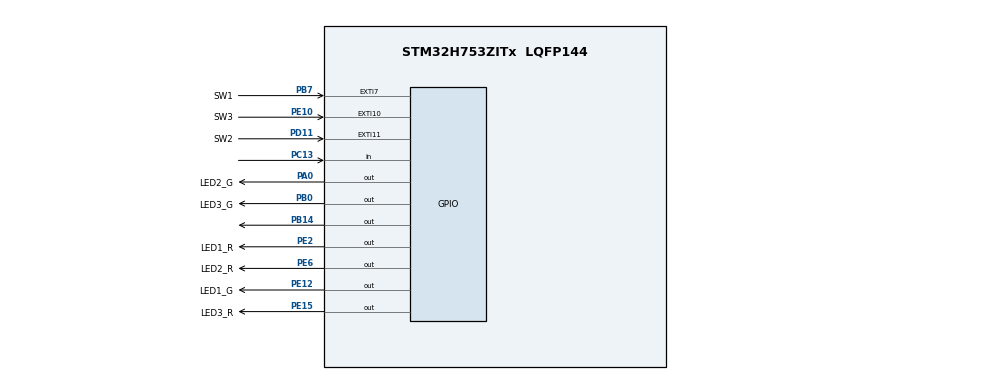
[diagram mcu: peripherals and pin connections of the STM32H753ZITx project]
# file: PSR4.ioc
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CORTEX_M7.CPU_DCache=Enabled
CORTEX_M7.CPU_ICache=Disabled
CORTEX_M7.MPU_Control=__NULL
CORTEX_M7.default_mode_Activation=1
Mcu.Family=STM32H7
Mcu.Name=STM32H753ZITx
Mcu.Package=LQFP144
NUCLEO-H753ZI.BUTTON=0
NUCLEO-H753ZI.LD1=false
NUCLEO-H753ZI.LD2=false
NUCLEO-H753ZI.LD3=false
NUCLEO-H753ZI.VCP=true
NVIC.EXTI15_10_IRQn=true\:0\:0\:false\:false\:true\:false\:true\:true\:true
NVIC.EXTI9_5_IRQn=true\:0\:0\:false\:false\:true\:false\:true\:true\:true
NVIC.PriorityGroup=NVIC_PRIORITYGROUP_4
NVIC.TIM3_IRQn=true\:0\:0\:false\:false\:true\:false\:true\:true\:true
NVIC.TIM6_DAC_IRQn=true\:15\:0\:false\:false\:true\:false\:false\:true\:true
NVIC.TimeBase=TIM6_DAC_IRQn
NVIC.TimeBaseIP=TIM6
PA0.GPIO_Label=LED2_G
PA0.PinState=GPIO_PIN_SET
PA0.Signal=GPIO_Output
PB0.GPIO_Label=LED3_G
PB0.PinState=GPIO_PIN_SET
PB0.Signal=GPIO_Output
PB14.Signal=GPIO_Output
PB7.GPIO_Label=SW1
PB7.GPIO_ModeDefaultEXTI=GPIO_MODE_IT_FALLING
PB7.Signal=GPXTI7
PC13.Signal=GPIO_Input
PC14-OSC32_IN\ (OSC32_IN).Signal=RCC_OSC32_IN
PC15-OSC32_OUT\ (OSC32_OUT).Signal=RCC_OSC32_OUT
PD11.GPIO_Label=SW2
PD11.GPIO_ModeDefaultEXTI=GPIO_MODE_IT_FALLING
PD11.Signal=GPXTI11
PD8.Signal=USART3_TX
PD9.Signal=USART3_RX
PE10.GPIO_Label=SW3
PE10.GPIO_ModeDefaultEXTI=GPIO_MODE_IT_FALLING
PE10.Signal=GPXTI10
PE12.GPIO_Label=LED1_G
PE12.PinState=GPIO_PIN_SET
PE12.Signal=GPIO_Output
PE15.GPIO_Label=LED3_R
PE15.PinState=GPIO_PIN_SET
PE15.Signal=GPIO_Output
PE2.GPIO_Label=LED1_R
PE2.PinState=GPIO_PIN_SET
PE2.Signal=GPIO_Output
PE6.GPIO_Label=LED2_R
PE6.PinState=GPIO_PIN_SET
PE6.Signal=GPIO_Output
PH0-OSC_IN\ (PH0).Signal=RCC_OSC_IN
PH1-OSC_OUT\ (PH1).Signal=RCC_OSC_OUT
ProjectManager.HeapSize=0x200
ProjectManager.StackSize=0x400
ProjectManager.TargetToolchain=STM32CubeIDE
RCC.ADCFreq_Value=129000000
RCC.APB1Freq_Value=120000000
RCC.APB2Freq_Value=120000000
RCC.APB3Freq_Value=120000000
RCC.APB4Freq_Value=120000000
RCC.CortexFreq_Value=480000000
RCC.D1PPRE=RCC_APB3_DIV2
RCC.D2PPRE1=RCC_APB1_DIV2
RCC.D2PPRE2=RCC_APB2_DIV2
RCC.D3PPRE=RCC_APB4_DIV2
RCC.DIVM1=4
RCC.DIVN1=60
RCC.DIVQ1=4
RCC.HCLKFreq_Value=240000000
RCC.HPRE=RCC_HCLK_DIV2
RCC.HSE_VALUE=8000000
RCC.PLLFRACN=0
RCC.PWR_Regulator_Voltage_Scale=PWR_REGULATOR_VOLTAGE_SCALE0
RCC.SYSCLKFreq_VALUE=480000000
RCC.SYSCLKSource=RCC_SYSCLKSOURCE_PLLCLK
RCC.USBFreq_Value=240000000
STMicroelectronics.X-CUBE-AZRTOS-H7.3.3.0.TX_APP_MEM_POOL_SIZE=(50*1024)
STMicroelectronics.X-CUBE-AZRTOS-H7.3.3.0.TX_ENABLE_EVENT_TRACE=1
STMicroelectronics.X-CUBE-AZRTOS-H7.3.3.0.ThreadXCcRTOSJjThreadXJjCore=true
STMicroelectronics.X-CUBE-AZRTOS-H7.3.3.0.ThreadXCcRTOSJjThreadXJjTraceXOosupport=true
STMicroelectronics.X-CUBE-AZRTOS-H7.3.3.0_IsAnAzureRtosMw=true
TIM3.Period=20
TIM3.Prescaler=239
VP_MEMORYMAP_VS_MEMORYMAP.Mode=CurAppReg
VP_NUCLEO-H753ZI_VS_BSP_COMMON.Mode=COMMON
VP_STMicroelectronics.X-CUBE-AZRTOS-H7_VS_RTOSJjThreadX_6.4.0_3.3.0.Mode=RTOSJjThreadX
VP_SYS_VS_tim6.Mode=TIM6
VP_TIM2_VS_ClockSourceINT.Mode=Internal
VP_TIM3_VS_ClockSourceINT.Mode=Internal
board=NUCLEO-H753ZI

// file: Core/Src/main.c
/* USER CODE BEGIN Header */
/**
  ******************************************************************************
  * @file           : main.c
  * @brief          : Main program body
  ******************************************************************************
  * @attention
  *
  * Copyright (c) 2025 STMicroelectronics.
  * All rights reserved.
  *
  * This software is licensed under terms that can be found in the LICENSE file
  * in the root directory of this software component.
  * If no LICENSE file comes with this software, it is provided AS-IS.
  *
  ******************************************************************************
  */
/* USER CODE END Header */
#include "app_threadx.h"
#include "main.h"

COM_InitTypeDef BspCOMInit;

TIM_HandleTypeDef htim2;
TIM_HandleTypeDef htim3;

void SystemClock_Config(void);
static void MX_GPIO_Init(void);
static void MX_TIM2_Init(void);
static void MX_TIM3_Init(void);

int main(void)
{

  /* Enable D-Cache---------------------------------------------------------*/
  SCB_EnableDCache();

  /* MCU Configuration--------------------------------------------------------*/

  /* Reset of all peripherals, Initializes the Flash interface and the Systick. */
  HAL_Init();

  /* Configure the system clock */
  SystemClock_Config();

  /* Initialize all configured peripherals */
  MX_GPIO_Init();
  MX_TIM2_Init();
  MX_TIM3_Init();
  /* USER CODE BEGIN 2 */
  HAL_TIM_Base_Start(&htim2);
  HAL_TIM_Base_Start_IT(&htim3);

  /* USER CODE END 2 */

  /* Initialize COM1 port (115200, 8 bits (7-bit data + 1 stop bit), no parity */
  BspCOMInit.BaudRate   = 115200;
  BspCOMInit.WordLength = COM_WORDLENGTH_8B;
  BspCOMInit.StopBits   = COM_STOPBITS_1;
  BspCOMInit.Parity     = COM_PARITY_NONE;
  BspCOMInit.HwFlowCtl  = COM_HWCONTROL_NONE;
  if (BSP_COM_Init(COM1, &BspCOMInit) != BSP_ERROR_NONE)
  {
    Error_Handler();
  }

  MX_ThreadX_Init();

  /* We should never get here as control is now taken by the scheduler */

  /* Infinite loop */
  while (1)
  {

  }
}

void SystemClock_Config(void)
{
  RCC_OscInitTypeDef RCC_OscInitStruct = {0};
  RCC_ClkInitTypeDef RCC_ClkInitStruct = {0};

  /** Supply configuration update enable
  */
  HAL_PWREx_ConfigSupply(PWR_LDO_SUPPLY);

  /** Configure the main internal regulator output voltage
  */
  __HAL_PWR_VOLTAGESCALING_CONFIG(PWR_REGULATOR_VOLTAGE_SCALE0);

  while(!__HAL_PWR_GET_FLAG(PWR_FLAG_VOSRDY)) {}

  /** Initializes the RCC Oscillators according to the specified parameters
  * in the RCC_OscInitTypeDef structure.
  */
  RCC_OscInitStruct.OscillatorType = RCC_OSCILLATORTYPE_HSI;
  RCC_OscInitStruct.HSIState = RCC_HSI_DIV1;
  RCC_OscInitStruct.HSICalibrationValue = RCC_HSICALIBRATION_DEFAULT;
  RCC_OscInitStruct.PLL.PLLState = RCC_PLL_ON;
  RCC_OscInitStruct.PLL.PLLSource = RCC_PLLSOURCE_HSI;
  RCC_OscInitStruct.PLL.PLLM = 4;
  RCC_OscInitStruct.PLL.PLLN = 60;
  RCC_OscInitStruct.PLL.PLLP = 2;
  RCC_OscInitStruct.PLL.PLLQ = 4;
  RCC_OscInitStruct.PLL.PLLR = 2;
  RCC_OscInitStruct.PLL.PLLRGE = RCC_PLL1VCIRANGE_3;
  RCC_OscInitStruct.PLL.PLLVCOSEL = RCC_PLL1VCOWIDE;
  RCC_OscInitStruct.PLL.PLLFRACN = 0;
  if (HAL_RCC_OscConfig(&RCC_OscInitStruct) != HAL_OK)
  {
    Error_Handler();
  }

  /** Initializes the CPU, AHB and APB buses clocks
  */
  RCC_ClkInitStruct.ClockType = RCC_CLOCKTYPE_HCLK|RCC_CLOCKTYPE_SYSCLK
                              |RCC_CLOCKTYPE_PCLK1|RCC_CLOCKTYPE_PCLK2
                              |RCC_CLOCKTYPE_D3PCLK1|RCC_CLOCKTYPE_D1PCLK1;
  RCC_ClkInitStruct.SYSCLKSource = RCC_SYSCLKSOURCE_PLLCLK;
  RCC_ClkInitStruct.SYSCLKDivider = RCC_SYSCLK_DIV1;
  RCC_ClkInitStruct.AHBCLKDivider = RCC_HCLK_DIV2;
  RCC_ClkInitStruct.APB3CLKDivider = RCC_APB3_DIV2;
  RCC_ClkInitStruct.APB1CLKDivider = RCC_APB1_DIV2;
  RCC_ClkInitStruct.APB2CLKDivider = RCC_APB2_DIV2;
  RCC_ClkInitStruct.APB4CLKDivider = RCC_APB4_DIV2;

  if (HAL_RCC_ClockConfig(&RCC_ClkInitStruct, FLASH_LATENCY_4) != HAL_OK)
  {
    Error_Handler();
  }
}

static void MX_TIM2_Init(void)
{

  TIM_ClockConfigTypeDef sClockSourceConfig = {0};
  TIM_MasterConfigTypeDef sMasterConfig = {0};

  htim2.Instance = TIM2;
  htim2.Init.Prescaler = 0;
  htim2.Init.CounterMode = TIM_COUNTERMODE_UP;
  htim2.Init.Period = 4294967295;
  htim2.Init.ClockDivision = TIM_CLOCKDIVISION_DIV1;
  htim2.Init.AutoReloadPreload = TIM_AUTORELOAD_PRELOAD_DISABLE;
  if (HAL_TIM_Base_Init(&htim2) != HAL_OK)
  {
    Error_Handler();
  }
  sClockSourceConfig.ClockSource = TIM_CLOCKSOURCE_INTERNAL;
  if (HAL_TIM_ConfigClockSource(&htim2, &sClockSourceConfig) != HAL_OK)
  {
    Error_Handler();
  }
  sMasterConfig.MasterOutputTrigger = TIM_TRGO_RESET;
  sMasterConfig.MasterSlaveMode = TIM_MASTERSLAVEMODE_DISABLE;
  if (HAL_TIMEx_MasterConfigSynchronization(&htim2, &sMasterConfig) != HAL_OK)
  {
    Error_Handler();
  }

}

static void MX_TIM3_Init(void)
{

  TIM_ClockConfigTypeDef sClockSourceConfig = {0};
  TIM_MasterConfigTypeDef sMasterConfig = {0};

  htim3.Instance = TIM3;
  htim3.Init.Prescaler = 239;
  htim3.Init.CounterMode = TIM_COUNTERMODE_UP;
  htim3.Init.Period = 20;
  htim3.Init.ClockDivision = TIM_CLOCKDIVISION_DIV1;
  htim3.Init.AutoReloadPreload = TIM_AUTORELOAD_PRELOAD_DISABLE;
  if (HAL_TIM_Base_Init(&htim3) != HAL_OK)
  {
    Error_Handler();
  }
  sClockSourceConfig.ClockSource = TIM_CLOCKSOURCE_INTERNAL;
  if (HAL_TIM_ConfigClockSource(&htim3, &sClockSourceConfig) != HAL_OK)
  {
    Error_Handler();
  }
  sMasterConfig.MasterOutputTrigger = TIM_TRGO_RESET;
  sMasterConfig.MasterSlaveMode = TIM_MASTERSLAVEMODE_DISABLE;
  if (HAL_TIMEx_MasterConfigSynchronization(&htim3, &sMasterConfig) != HAL_OK)
  {
    Error_Handler();
  }

}

static void MX_GPIO_Init(void)
{
  GPIO_InitTypeDef GPIO_InitStruct = {0};

  /* GPIO Ports Clock Enable */
  __HAL_RCC_GPIOE_CLK_ENABLE();
  __HAL_RCC_GPIOC_CLK_ENABLE();
  __HAL_RCC_GPIOH_CLK_ENABLE();
  __HAL_RCC_GPIOA_CLK_ENABLE();
  __HAL_RCC_GPIOB_CLK_ENABLE();
  __HAL_RCC_GPIOD_CLK_ENABLE();

  /*Configure GPIO pin Output Level */
  HAL_GPIO_WritePin(GPIOE, LED1_R_Pin|LED2_R_Pin|LED1_G_Pin|LED3_R_Pin, GPIO_PIN_SET);

  /*Configure GPIO pin Output Level */
  HAL_GPIO_WritePin(LED2_G_GPIO_Port, LED2_G_Pin, GPIO_PIN_SET);

  /*Configure GPIO pin Output Level */
  HAL_GPIO_WritePin(LED3_G_GPIO_Port, LED3_G_Pin, GPIO_PIN_SET);

  /*Configure GPIO pin Output Level */
  HAL_GPIO_WritePin(GPIOB, GPIO_PIN_14, GPIO_PIN_RESET);

  /*Configure GPIO pins : LED1_R_Pin LED2_R_Pin LED1_G_Pin LED3_R_Pin */
  GPIO_InitStruct.Pin = LED1_R_Pin|LED2_R_Pin|LED1_G_Pin|LED3_R_Pin;
  GPIO_InitStruct.Mode = GPIO_MODE_OUTPUT_PP;
  GPIO_InitStruct.Pull = GPIO_NOPULL;
  GPIO_InitStruct.Speed = GPIO_SPEED_FREQ_LOW;
  HAL_GPIO_Init(GPIOE, &GPIO_InitStruct);

  /*Configure GPIO pin : PC13 */
  GPIO_InitStruct.Pin = GPIO_PIN_13;
  GPIO_InitStruct.Mode = GPIO_MODE_INPUT;
  GPIO_InitStruct.Pull = GPIO_NOPULL;
  HAL_GPIO_Init(GPIOC, &GPIO_InitStruct);

  /*Configure GPIO pin : LED2_G_Pin */
  GPIO_InitStruct.Pin = LED2_G_Pin;
  GPIO_InitStruct.Mode = GPIO_MODE_OUTPUT_PP;
  GPIO_InitStruct.Pull = GPIO_NOPULL;
  GPIO_InitStruct.Speed = GPIO_SPEED_FREQ_LOW;
  HAL_GPIO_Init(LED2_G_GPIO_Port, &GPIO_InitStruct);

  /*Configure GPIO pins : LED3_G_Pin PB14 */
  GPIO_InitStruct.Pin = LED3_G_Pin|GPIO_PIN_14;
  GPIO_InitStruct.Mode = GPIO_MODE_OUTPUT_PP;
  GPIO_InitStruct.Pull = GPIO_NOPULL;
  GPIO_InitStruct.Speed = GPIO_SPEED_FREQ_LOW;
  HAL_GPIO_Init(GPIOB, &GPIO_InitStruct);

  /*Configure GPIO pin : SW3_Pin */
  GPIO_InitStruct.Pin = SW3_Pin;
  GPIO_InitStruct.Mode = GPIO_MODE_IT_FALLING;
  GPIO_InitStruct.Pull = GPIO_NOPULL;
  HAL_GPIO_Init(SW3_GPIO_Port, &GPIO_InitStruct);

  /*Configure GPIO pins : PD8 PD9 */
  GPIO_InitStruct.Pin = GPIO_PIN_8|GPIO_PIN_9;
  GPIO_InitStruct.Mode = GPIO_MODE_AF_PP;
  GPIO_InitStruct.Pull = GPIO_NOPULL;
  GPIO_InitStruct.Speed = GPIO_SPEED_FREQ_LOW;
  GPIO_InitStruct.Alternate = GPIO_AF7_USART3;
  HAL_GPIO_Init(GPIOD, &GPIO_InitStruct);

  /*Configure GPIO pin : SW2_Pin */
  GPIO_InitStruct.Pin = SW2_Pin;
  GPIO_InitStruct.Mode = GPIO_MODE_IT_FALLING;
  GPIO_InitStruct.Pull = GPIO_NOPULL;
  HAL_GPIO_Init(SW2_GPIO_Port, &GPIO_InitStruct);

  /*Configure GPIO pin : SW1_Pin */
  GPIO_InitStruct.Pin = SW1_Pin;
  GPIO_InitStruct.Mode = GPIO_MODE_IT_FALLING;
  GPIO_InitStruct.Pull = GPIO_NOPULL;
  HAL_GPIO_Init(SW1_GPIO_Port, &GPIO_InitStruct);

  /*AnalogSwitch Config */
  HAL_SYSCFG_AnalogSwitchConfig(SYSCFG_SWITCH_PA0, SYSCFG_SWITCH_PA0_CLOSE);

  /* EXTI interrupt init*/
  HAL_NVIC_SetPriority(SW1_EXTI_IRQn, 0, 0);
  HAL_NVIC_EnableIRQ(SW1_EXTI_IRQn);

  HAL_NVIC_SetPriority(SW3_EXTI_IRQn, 0, 0);
  HAL_NVIC_EnableIRQ(SW3_EXTI_IRQn);

}

void HAL_TIM_PeriodElapsedCallback(TIM_HandleTypeDef *htim)
{
  if (htim->Instance == TIM6)
  {
    HAL_IncTick();
  }
}

void Error_Handler(void)
{
  __disable_irq();
  while (1)
  {
  }
}
